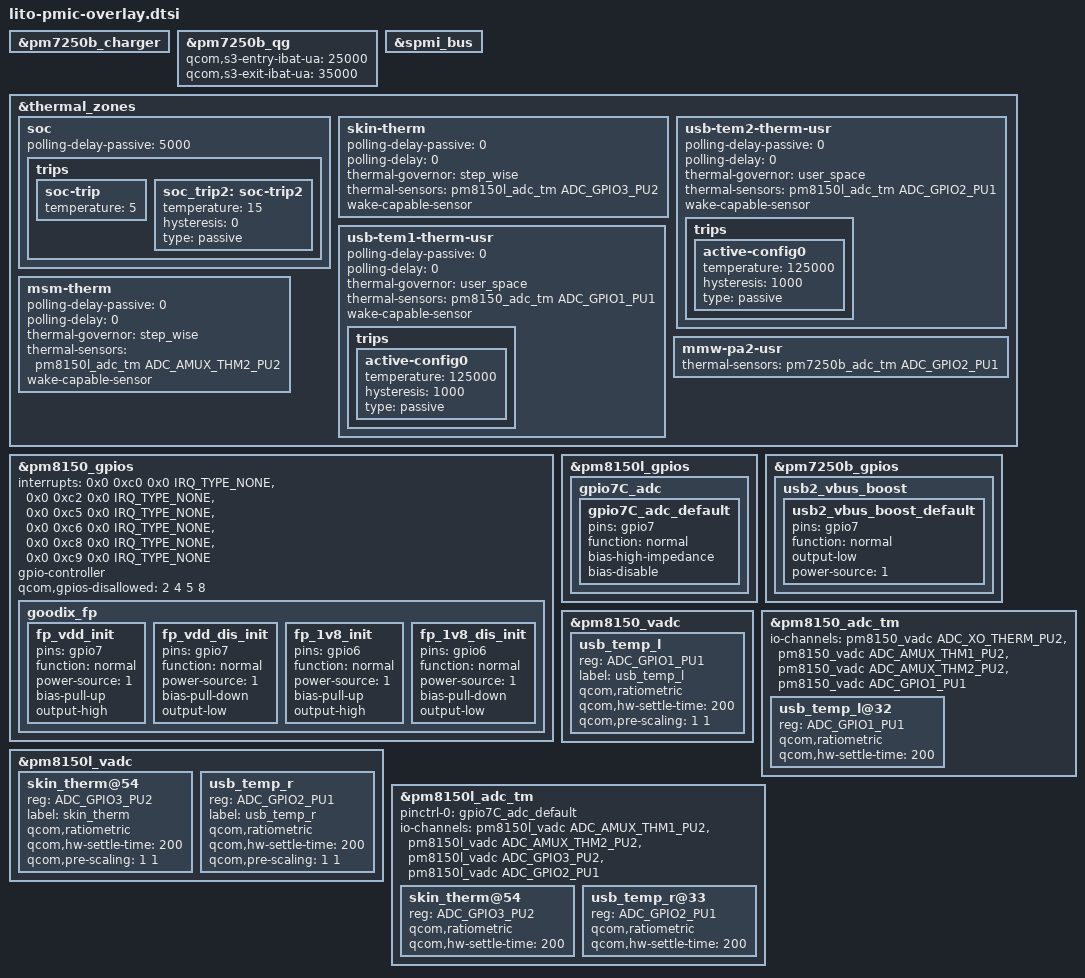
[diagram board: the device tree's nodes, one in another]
#include "../../qcom/lito-pmic-overlay.dtsi"

&pm7250b_charger {
	/delete-property/ qcom,hvdcp2-max-icl-ua;
	/delete-property/ qcom,hvdcp2-12v-max-icl-ua;
};

&pm7250b_qg {
	qcom,s3-entry-ibat-ua = <25000>;
	qcom,s3-exit-ibat-ua = <35000>;
};

&spmi_bus {
	/delete-node/ qcom,pm7250b@3;
};

&thermal_zones {
	soc {
		polling-delay-passive = <5000>;
		trips {
			soc-trip {
				temperature = <5>;
			};

			soc_trip2: soc-trip2 {
				temperature = <15>;
				hysteresis = <0>;
				type = "passive";
			};
		};
	};

	skin-therm {
		polling-delay-passive = <0>;
		polling-delay = <0>;
		thermal-governor = "step_wise";
		thermal-sensors = <&pm8150l_adc_tm ADC_GPIO3_PU2>;
		wake-capable-sensor;
	};

	usb-tem2-therm-usr {
		polling-delay-passive = <0>;
		polling-delay = <0>;
		thermal-governor = "user_space";
		thermal-sensors = <&pm8150l_adc_tm ADC_GPIO2_PU1>;
		wake-capable-sensor;
		trips {
			active-config0 {
				temperature = <125000>;
				hysteresis = <1000>;
				type = "passive";
			};
		};
	};

	usb-tem1-therm-usr {
		polling-delay-passive = <0>;
		polling-delay = <0>;
		thermal-governor = "user_space";
		thermal-sensors = <&pm8150_adc_tm ADC_GPIO1_PU1>;
		wake-capable-sensor;
		trips {
			active-config0 {
				temperature = <125000>;
				hysteresis = <1000>;
				type = "passive";
			};
		};
	};

	mmw-pa2-usr {
		thermal-sensors = <&pm7250b_adc_tm ADC_GPIO2_PU1>;
	};

	msm-therm {
		polling-delay-passive = <0>;
		polling-delay = <0>;
		thermal-governor = "step_wise";
		thermal-sensors = <&pm8150l_adc_tm ADC_AMUX_THM2_PU2>;
		wake-capable-sensor;
	};
};

&pm8150_gpios {
	interrupts = <0x0 0xc0 0x0 IRQ_TYPE_NONE>,
		<0x0 0xc2 0x0 IRQ_TYPE_NONE>,
		<0x0 0xc5 0x0 IRQ_TYPE_NONE>,
		<0x0 0xc6 0x0 IRQ_TYPE_NONE>,
		<0x0 0xc8 0x0 IRQ_TYPE_NONE>,
		<0x0 0xc9 0x0 IRQ_TYPE_NONE>;
	interrupt-names = "pm8150_gpio1", "pm8150_gpio3",
		"pm8150_gpio6", "pm8150_gpio7",
		"pm8150_gpio9", "pm8150_gpio10";
	gpio-controller;
	#gpio-cells = <2>;
	qcom,gpios-disallowed = <2 4 5 8>;
	goodix_fp {
		fp_vdd_init: fp_vdd_init {
			pins = "gpio7";
			function = "normal";
			power-source = <1>;
			bias-pull-up;
			output-high;
		};

		fp_vdd_dis_init: fp_vdd_dis_init {
			pins = "gpio7";
			function = "normal";
			power-source = <1>;
			bias-pull-down;
			output-low;
		};

		fp_1v8_init: fp_1v8_init {
			pins = "gpio6";
			function = "normal";
			power-source = <1>;
			bias-pull-up;
			output-high;
		};

		fp_1v8_dis_init: fp_1v8_dis_init {
			pins = "gpio6";
			function = "normal";
			power-source = <1>;
			bias-pull-down;
			output-low;
		};
	};
};

&pm8150l_gpios {
	gpio7C_adc {
		gpio7C_adc_default: gpio7C_adc_default {
			pins = "gpio7";
			function = "normal";
			bias-high-impedance;
			bias-disable;
		};
	};
};

&pm7250b_gpios {
	usb2_vbus_boost {
		usb2_vbus_boost_default: usb2_vbus_boost_default {
			pins = "gpio7";
			function = "normal";
			output-low;
			power-source = <1>;
		};
	};
};

&pm8150_vadc {
	usb_temp_l {
		reg = <ADC_GPIO1_PU1>;
		label = "usb_temp_l";
		qcom,ratiometric;
		qcom,hw-settle-time = <200>;
		qcom,pre-scaling = <1 1>;
	};
};

&pm8150l_vadc {
	/delete-node/ bmr_n_therm@4f;
	skin_therm@54 {
		reg = <ADC_GPIO3_PU2>;
		label = "skin_therm";
		qcom,ratiometric;
		qcom,hw-settle-time = <200>;
		qcom,pre-scaling = <1 1>;
	};

	usb_temp_r {
		reg = <ADC_GPIO2_PU1>;
		label = "usb_temp_r";
		qcom,ratiometric;
		qcom,hw-settle-time = <200>;
		qcom,pre-scaling = <1 1>;
	};
};

&pm8150_adc_tm {
	io-channels = <&pm8150_vadc ADC_XO_THERM_PU2>,
		<&pm8150_vadc ADC_AMUX_THM1_PU2>,
		<&pm8150_vadc ADC_AMUX_THM2_PU2>,
		<&pm8150_vadc ADC_GPIO1_PU1>;
	usb_temp_l@32 {
		reg = <ADC_GPIO1_PU1>;
		qcom,ratiometric;
		qcom,hw-settle-time = <200>;
	};
};

&pm8150l_adc_tm {
	pinctrl-names = "default";
	pinctrl-0 = <&gpio7C_adc_default>;
	io-channels = <&pm8150l_vadc ADC_AMUX_THM1_PU2>,
		<&pm8150l_vadc ADC_AMUX_THM2_PU2>,
		<&pm8150l_vadc ADC_GPIO3_PU2>,
		<&pm8150l_vadc ADC_GPIO2_PU1>;
	/delete-node/ bmr_n_therm@4f;
	skin_therm@54 {
		reg = <ADC_GPIO3_PU2>;
		qcom,ratiometric;
		qcom,hw-settle-time = <200>;
	};

	usb_temp_r@33 {
		reg = <ADC_GPIO2_PU1>;
		qcom,ratiometric;
		qcom,hw-settle-time = <200>;
	};
};
